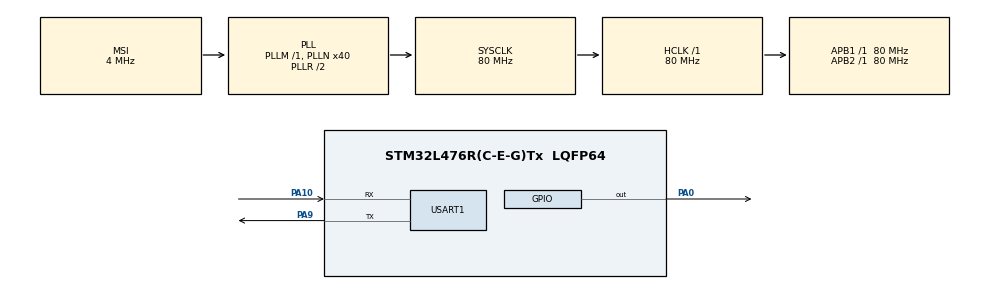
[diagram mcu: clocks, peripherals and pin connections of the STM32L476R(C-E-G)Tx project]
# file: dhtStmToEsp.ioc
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Mcu.Family=STM32L4
Mcu.Name=STM32L476R(C-E-G)Tx
Mcu.Package=LQFP64
NVIC.PriorityGroup=NVIC_PRIORITYGROUP_4
PA0.Signal=GPIO_Output
PA10.Mode=Asynchronous
PA10.Signal=USART1_RX
PA13\ (JTMS-SWDIO).Mode=Serial_Wire
PA13\ (JTMS-SWDIO).Signal=SYS_JTMS-SWDIO
PA14\ (JTCK-SWCLK).Mode=Serial_Wire
PA14\ (JTCK-SWCLK).Signal=SYS_JTCK-SWCLK
PA9.Mode=Asynchronous
PA9.Signal=USART1_TX
PH0-OSC_IN\ (PH0).Mode=HSE-External-Oscillator
PH0-OSC_IN\ (PH0).Signal=RCC_OSC_IN
PH1-OSC_OUT\ (PH1).Mode=HSE-External-Oscillator
PH1-OSC_OUT\ (PH1).Signal=RCC_OSC_OUT
ProjectManager.HeapSize=0x200
ProjectManager.StackSize=0x400
ProjectManager.TargetToolchain=STM32CubeIDE
RCC.AHBFreq_Value=80000000
RCC.APB1Freq_Value=80000000
RCC.APB1TimFreq_Value=80000000
RCC.APB2Freq_Value=80000000
RCC.APB2TimFreq_Value=80000000
RCC.CortexFreq_Value=80000000
RCC.HCLKFreq_Value=80000000
RCC.HSE_VALUE=8000000
RCC.HSI_VALUE=16000000
RCC.LSE_VALUE=32768
RCC.MSI_VALUE=4000000
RCC.PLLN=40
RCC.SYSCLKFreq_VALUE=80000000
RCC.SYSCLKSource=RCC_SYSCLKSOURCE_PLLCLK
RCC.VCOOutputFreq_Value=160000000
TIM6.Prescaler=79
USART1.VirtualMode-Asynchronous=VM_ASYNC
VP_TIM6_VS_ClockSourceINT.Mode=Enable_Timer
board=custom

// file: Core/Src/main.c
/* USER CODE BEGIN Header */
/**
  ******************************************************************************
  * @file           : main.c
  * @brief          : Main program body
  ******************************************************************************
  * @attention
  *
  * Copyright (c) 2025 STMicroelectronics.
  * All rights reserved.
  *
  * This software is licensed under terms that can be found in the LICENSE file
  * in the root directory of this software component.
  * If no LICENSE file comes with this software, it is provided AS-IS.
  *
  ******************************************************************************
  */
/* USER CODE END Header */
#include "main.h"

/* USER CODE BEGIN PD */
#define DHT11_PORT GPIOA
#define DHT11_PIN GPIO_PIN_0
/* USER CODE END PD */

TIM_HandleTypeDef htim6;

UART_HandleTypeDef huart1;

/* USER CODE BEGIN PV */
uint8_t dht11_data[5];         // Array to store DHT11 40-bit data
volatile uint8_t temperature;  // Temperature value for tracing
extern volatile uint32_t tick_count;  // Declared as extern, defined in stm32l4xx_it.c
/* USER CODE END PV */

void SystemClock_Config(void);
static void MX_GPIO_Init(void);
static void MX_TIM6_Init(void);
static void MX_USART1_UART_Init(void);

void delay_us(uint16_t us);
void DHT11_Start(void);
uint8_t DHT11_Read(void);

/* USER CODE BEGIN PFP */

/* Redirect printf to SWV ITM */
int _write(int file, char *ptr, int len)
{
    int i;
    for (i = 0; i < len; i++) {
        ITM_SendChar(*ptr++);
    }
    return len;
}
/* USER CODE END PFP */

int main(void)
{
  /* USER CODE BEGIN 1 */
	char msg[50];
	  char uart_msg[50];  // Buffer for UART transmission
  /* USER CODE END 1 */

  /* MCU Configuration--------------------------------------------------------*/

  /* Reset of all peripherals, Initializes the Flash interface and the Systick. */
  HAL_Init();

  /* Configure the system clock */
  SystemClock_Config();

  /* Initialize all configured peripherals */
  MX_GPIO_Init();
  MX_TIM6_Init();
  MX_USART1_UART_Init();
  /* USER CODE BEGIN 2 */
  /* USER CODE BEGIN 2 */
    HAL_TIM_Base_Start(&htim6); // Start TIM6 for microsecond delays
    printf("DHT11 Temperature Test via SWV\n");
  /* USER CODE END 2 */

  /* Infinite loop */
  /* USER CODE BEGIN WHILE */
    while (1)
      {
        if (DHT11_Read() == 0) { // If data read successfully
          temperature = dht11_data[2]; // Update temperature for tracing
          sprintf(msg, "Temperature: %d C\n", temperature);
          printf("%s", msg); // Send to ITM Data Console (SWV)

          // Prepare and send data via USART1 to Wemos
          sprintf(uart_msg, "Temp: %d C\r\n", temperature);
          HAL_UART_Transmit(&huart1, (uint8_t *)uart_msg, strlen(uart_msg), 100);
        } else {
          printf("Error reading DHT11\n");
          temperature = 0; // Reset for tracing
          sprintf(uart_msg, "Error reading DHT11\r\n");
          HAL_UART_Transmit(&huart1, (uint8_t *)uart_msg, strlen(uart_msg), 100);
        }
        HAL_Delay(2000); // DHT11 needs at least 2 seconds between readings
        /* USER CODE END WHILE */

      }
}

void SystemClock_Config(void)
{
  RCC_OscInitTypeDef RCC_OscInitStruct = {0};
  RCC_ClkInitTypeDef RCC_ClkInitStruct = {0};

  /** Configure the main internal regulator output voltage
  */
  if (HAL_PWREx_ControlVoltageScaling(PWR_REGULATOR_VOLTAGE_SCALE1) != HAL_OK)
  {
    Error_Handler();
  }

  /** Initializes the RCC Oscillators according to the specified parameters
  * in the RCC_OscInitTypeDef structure.
  */
  RCC_OscInitStruct.OscillatorType = RCC_OSCILLATORTYPE_MSI;
  RCC_OscInitStruct.MSIState = RCC_MSI_ON;
  RCC_OscInitStruct.MSICalibrationValue = 0;
  RCC_OscInitStruct.MSIClockRange = RCC_MSIRANGE_6;
  RCC_OscInitStruct.PLL.PLLState = RCC_PLL_ON;
  RCC_OscInitStruct.PLL.PLLSource = RCC_PLLSOURCE_MSI;
  RCC_OscInitStruct.PLL.PLLM = 1;
  RCC_OscInitStruct.PLL.PLLN = 40;
  RCC_OscInitStruct.PLL.PLLP = RCC_PLLP_DIV7;
  RCC_OscInitStruct.PLL.PLLQ = RCC_PLLQ_DIV2;
  RCC_OscInitStruct.PLL.PLLR = RCC_PLLR_DIV2;
  if (HAL_RCC_OscConfig(&RCC_OscInitStruct) != HAL_OK)
  {
    Error_Handler();
  }

  /** Initializes the CPU, AHB and APB buses clocks
  */
  RCC_ClkInitStruct.ClockType = RCC_CLOCKTYPE_HCLK|RCC_CLOCKTYPE_SYSCLK
                              |RCC_CLOCKTYPE_PCLK1|RCC_CLOCKTYPE_PCLK2;
  RCC_ClkInitStruct.SYSCLKSource = RCC_SYSCLKSOURCE_PLLCLK;
  RCC_ClkInitStruct.AHBCLKDivider = RCC_SYSCLK_DIV1;
  RCC_ClkInitStruct.APB1CLKDivider = RCC_HCLK_DIV1;
  RCC_ClkInitStruct.APB2CLKDivider = RCC_HCLK_DIV1;

  if (HAL_RCC_ClockConfig(&RCC_ClkInitStruct, FLASH_LATENCY_4) != HAL_OK)
  {
    Error_Handler();
  }
}

static void MX_TIM6_Init(void)
{

  TIM_MasterConfigTypeDef sMasterConfig = {0};

  htim6.Instance = TIM6;
  htim6.Init.Prescaler = 79;
  htim6.Init.CounterMode = TIM_COUNTERMODE_UP;
  htim6.Init.Period = 65535;
  htim6.Init.AutoReloadPreload = TIM_AUTORELOAD_PRELOAD_DISABLE;
  if (HAL_TIM_Base_Init(&htim6) != HAL_OK)
  {
    Error_Handler();
  }
  sMasterConfig.MasterOutputTrigger = TIM_TRGO_RESET;
  sMasterConfig.MasterSlaveMode = TIM_MASTERSLAVEMODE_DISABLE;
  if (HAL_TIMEx_MasterConfigSynchronization(&htim6, &sMasterConfig) != HAL_OK)
  {
    Error_Handler();
  }

}

static void MX_USART1_UART_Init(void)
{

  huart1.Instance = USART1;
  huart1.Init.BaudRate = 115200;
  huart1.Init.WordLength = UART_WORDLENGTH_8B;
  huart1.Init.StopBits = UART_STOPBITS_1;
  huart1.Init.Parity = UART_PARITY_NONE;
  huart1.Init.Mode = UART_MODE_TX_RX;
  huart1.Init.HwFlowCtl = UART_HWCONTROL_NONE;
  huart1.Init.OverSampling = UART_OVERSAMPLING_16;
  huart1.Init.OneBitSampling = UART_ONE_BIT_SAMPLE_DISABLE;
  huart1.AdvancedInit.AdvFeatureInit = UART_ADVFEATURE_NO_INIT;
  if (HAL_UART_Init(&huart1) != HAL_OK)
  {
    Error_Handler();
  }

}

static void MX_GPIO_Init(void)
{
  GPIO_InitTypeDef GPIO_InitStruct = {0};

  /* GPIO Ports Clock Enable */
  __HAL_RCC_GPIOH_CLK_ENABLE();
  __HAL_RCC_GPIOA_CLK_ENABLE();

  /*Configure GPIO pin Output Level */
  HAL_GPIO_WritePin(GPIOA, GPIO_PIN_0, GPIO_PIN_RESET);

  /*Configure GPIO pin : PA0 */
  GPIO_InitStruct.Pin = GPIO_PIN_0;
  GPIO_InitStruct.Mode = GPIO_MODE_OUTPUT_PP;
  GPIO_InitStruct.Pull = GPIO_NOPULL;
  GPIO_InitStruct.Speed = GPIO_SPEED_FREQ_LOW;
  HAL_GPIO_Init(GPIOA, &GPIO_InitStruct);

}

/* USER CODE BEGIN 4 */
void delay_us(uint16_t us)
{
  __HAL_TIM_SET_COUNTER(&htim6, 0);
  while (__HAL_TIM_GET_COUNTER(&htim6) < us);
}

void DHT11_Start(void)
{
  GPIO_InitTypeDef GPIO_InitStruct = {0};
  GPIO_InitStruct.Pin = DHT11_PIN;
  GPIO_InitStruct.Mode = GPIO_MODE_OUTPUT_PP;
  GPIO_InitStruct.Pull = GPIO_NOPULL;
  GPIO_InitStruct.Speed = GPIO_SPEED_FREQ_LOW;
  HAL_GPIO_Init(DHT11_PORT, &GPIO_InitStruct);

  HAL_GPIO_WritePin(DHT11_PORT, DHT11_PIN, 0); // Pull low
  delay_us(18000); // 18 ms low pulse
  HAL_GPIO_WritePin(DHT11_PORT, DHT11_PIN, 1); // Pull high
  delay_us(20); // 20-40 µs high

  GPIO_InitStruct.Mode = GPIO_MODE_INPUT;
  HAL_GPIO_Init(DHT11_PORT, &GPIO_InitStruct); // Switch to input
}

uint8_t DHT11_Read(void)
{
  uint8_t i, j;
  DHT11_Start();
  delay_us(40); // Wait for DHT11 response

  if (HAL_GPIO_ReadPin(DHT11_PORT, DHT11_PIN) != 0) return 1; // No response
  delay_us(80);
  if (HAL_GPIO_ReadPin(DHT11_PORT, DHT11_PIN) == 0) return 1; // Invalid response
  delay_us(80);

  for (j = 0; j < 5; j++) {
    uint8_t result = 0;
    for (i = 0; i < 8; i++) {
      while (HAL_GPIO_ReadPin(DHT11_PORT, DHT11_PIN) == 0); // Wait for high
      delay_us(40); // Wait to determine bit length
      if (HAL_GPIO_ReadPin(DHT11_PORT, DHT11_PIN) == 1) { // High > 40 µs = 1
        result |= (1 << (7 - i));
      }
      while (HAL_GPIO_ReadPin(DHT11_PORT, DHT11_PIN) == 1); // Wait for low
    }
    dht11_data[j] = result;
  }

  if (dht11_data[4] != (dht11_data[0] + dht11_data[1] + dht11_data[2] + dht11_data[3])) {
    return 1; // Checksum error
  }
  return 0; // Success
}
/* USER CODE END 4 */

void Error_Handler(void)
{
  __disable_irq();
  while (1)
  {
  }
}
